AUTOSAR XML (schema 4-2-1)
# Copyright (c) 2017 Vector Informatik GmbH.
# License is restricted to the usage with CBD1500710 (D05) for MSR_Vector_SLP4.
# Please contact Vector Informatik whenever you need further information concerning the license conditions.
standard types defined: boolean, sint8, uint16, uint32, uint8
package /VehicleProject
  system System
package /NM
  nm config NmConfig: can-nm-cluster-coupling=coupled-cluster=CAN00_CAN
    can nm cluster CAN00_CAN: communication-cluster=CAN00, nm-channel-id=0, nm-user-data-length=6
      can nm node BSI: nm-if-ecu=BSI_CAN, nm-node-id=18, nm-passive-mode-enabled=true
      can nm node HDC: controller=CT_CAN00, nm-if-ecu=HDC_CAN, nm-node-id=45, nm-passive-mode-enabled=true
    nm-if-ecus:
      nm ecu BSI_CAN: nm-node-id-enabled=true, nm-passive-mode-enabled=true, nm-user-data-enabled=true
      nm ecu HDC_CAN: ecu-instance=HDC, nm-node-id-enabled=true, nm-passive-mode-enabled=true, nm-user-data-enabled=true
package /TP
  can tp config CAN00_CAN: communication-cluster=CAN00, can-tp-ecu{cycle-time-main-function=0.005, ecu-instance=HDC}
    can tp node TN_BSI
    can tp node TN_HDC: connector=CN_CAN00
package /Cluster
  can cluster CAN00: protocol-name=CAN  # COM2020_HSLS
    can physical channel CHNL: comm-connectors=CN_CAN00
      frame CAR_ACK_EVT_DEF_oCAN00: id 0x476, to HDC, frame-length=1, can-addressing-mode=STANDARD
        pdu CAR_ACK_EVT_DEF_oCAN00: length=1, minimum-delay=0, unused-bit-pattern=0
          signal REP_UCE_oCAR_ACK_EVT_DEF_oCAN00: start 0, 8 bit, little-endian, init-value=0, base-type=uint8, compu {0..255=RANGE}, transfer-property=PENDING, to HDC
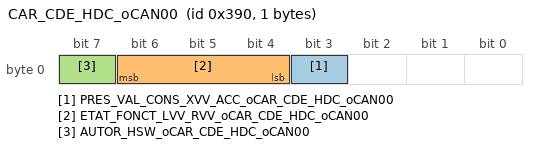
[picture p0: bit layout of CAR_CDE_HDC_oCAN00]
      frame CAR_CDE_HDC_oCAN00: id 0x390, to HDC, frame-length=1, can-addressing-mode=STANDARD
        pdu CAR_CDE_HDC_oCAN00: length=1, minimum-delay=0, transmission-mode-false-timing=event-controlled-timing={number-of-repetitions=0, repetition-period=0}, transmission-mode-true-timing=event-controlled-timing={number-of-repetitions=0, repetition-period=0}, unused-bit-pattern=0
          signal PRES_VAL_CONS_XVV_ACC_oCAR_CDE_HDC_oCAN00: start 3, 1 bit, big-endian, init-value=0, base-type=boolean, compu {0..1=RANGE}, transfer-property=TRIGGERED-ON-CHANGE-WITHOUT-REPETITION, to HDC
          signal ETAT_FONCT_LVV_RVV_oCAR_CDE_HDC_oCAN00: start 6, 3 bit, big-endian, init-value=0, base-type=uint8, compu {0..7=RANGE}, transfer-property=TRIGGERED-ON-CHANGE-WITHOUT-REPETITION, to HDC
          signal AUTOR_HSW_oCAR_CDE_HDC_oCAN00: start 7, 1 bit, big-endian, init-value=0, base-type=boolean, compu {0..1=RANGE}, transfer-property=TRIGGERED-ON-CHANGE-WITHOUT-REPETITION, to HDC
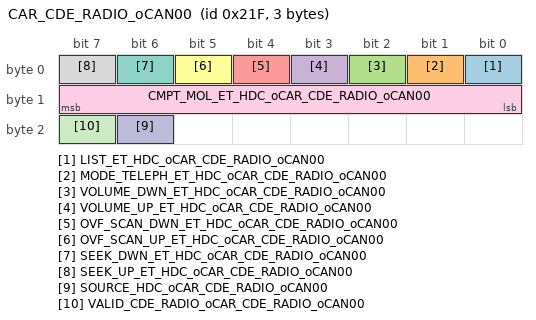
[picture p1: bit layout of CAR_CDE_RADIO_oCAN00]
      frame CAR_CDE_RADIO_oCAN00: id 0x21F, from HDC, frame-length=3, can-addressing-mode=STANDARD
        pdu CAR_CDE_RADIO_oCAN00: length=3, minimum-delay=0.05, transmission-mode-false-timing=event-controlled-timing={number-of-repetitions=0, repetition-period=0}, transmission-mode-true-timing=event-controlled-timing={number-of-repetitions=0, repetition-period=0}, unused-bit-pattern=0
          signal LIST_ET_HDC_oCAR_CDE_RADIO_oCAN00: start 0, 1 bit, big-endian, init-value=0, base-type=boolean, compu {0..1=RANGE}, transfer-property=PENDING
          signal MODE_TELEPH_ET_HDC_oCAR_CDE_RADIO_oCAN00: start 1, 1 bit, big-endian, init-value=0, base-type=boolean, compu {0..1=RANGE}, transfer-property=TRIGGERED-ON-CHANGE-WITHOUT-REPETITION
          signal VOLUME_DWN_ET_HDC_oCAR_CDE_RADIO_oCAN00: start 2, 1 bit, big-endian, init-value=0, base-type=boolean, compu {0..1=RANGE}, transfer-property=TRIGGERED-ON-CHANGE-WITHOUT-REPETITION
          signal VOLUME_UP_ET_HDC_oCAR_CDE_RADIO_oCAN00: start 3, 1 bit, big-endian, init-value=0, base-type=boolean, compu {0..1=RANGE}, transfer-property=TRIGGERED-ON-CHANGE-WITHOUT-REPETITION
          signal OVF_SCAN_DWN_ET_HDC_oCAR_CDE_RADIO_oCAN00: start 4, 1 bit, big-endian, init-value=0, base-type=boolean, compu {0..1=RANGE}, transfer-property=TRIGGERED-ON-CHANGE-WITHOUT-REPETITION
          signal OVF_SCAN_UP_ET_HDC_oCAR_CDE_RADIO_oCAN00: start 5, 1 bit, big-endian, init-value=0, base-type=boolean, compu {0..1=RANGE}, transfer-property=TRIGGERED-ON-CHANGE-WITHOUT-REPETITION
          signal SEEK_DWN_ET_HDC_oCAR_CDE_RADIO_oCAN00: start 6, 1 bit, big-endian, init-value=0, base-type=boolean, compu {0..1=RANGE}, transfer-property=TRIGGERED-ON-CHANGE-WITHOUT-REPETITION
          signal SEEK_UP_ET_HDC_oCAR_CDE_RADIO_oCAN00: start 7, 1 bit, big-endian, init-value=0, base-type=boolean, compu {0..1=RANGE}, transfer-property=TRIGGERED-ON-CHANGE-WITHOUT-REPETITION
          signal CMPT_MOL_ET_HDC_oCAR_CDE_RADIO_oCAN00: start 15, 8 bit, big-endian, init-value=0, base-type=sint8, compu {-128..127=RANGE}, transfer-property=TRIGGERED-ON-CHANGE-WITHOUT-REPETITION
          signal SOURCE_HDC_oCAR_CDE_RADIO_oCAN00: start 22, 1 bit, big-endian, init-value=0, base-type=boolean, compu {0..1=RANGE}, transfer-property=PENDING
          signal VALID_CDE_RADIO_oCAR_CDE_RADIO_oCAN00: start 23, 1 bit, big-endian, init-value=0, base-type=boolean, compu {0..1=RANGE}, transfer-property=PENDING
      frame CAR_CMD_AUTHENT_oCAN00: id 0xC2, to HDC, frame-length=8, can-addressing-mode=STANDARD
        pdu CAR_CMD_AUTHENT_oCAN00: length=8, minimum-delay=0, unused-bit-pattern=0
          signal RN_TRSP_CMD_TRSP_oCAR_CMD_AUTHENT_oCAN00: start 7, 32 bit, big-endian, init-value=0, base-type=uint32, compu {0..4294967295=RANGE}, transfer-property=PENDING, to HDC
          signal LPCRYPTE_CMD_TRSP_oCAR_CMD_AUTHENT_oCAN00: start 39, 32 bit, big-endian, init-value=0, base-type=uint32, compu {0..4294967295=RANGE}, transfer-property=PENDING, to HDC
      frame CAR_CMD_AUTHENT_MDP_AES_oCAN00: id 0x42, to HDC, frame-length=2, can-addressing-mode=STANDARD
        pdu CAR_CMD_AUTHENT_MDP_AES_oCAN00: length=2, minimum-delay=0, unused-bit-pattern=0
          signal LPCRYPTE_CMD_TRSP_AES_oCAR_CMD_AUTHENT_MDP_AES_oCAN00: start 7, 16 bit, big-endian, init-value=0, base-type=uint16, compu {0..65535=RANGE}, transfer-property=PENDING, to HDC
      frame CAR_CMD_AUTHENT_RND_AES_oCAN00: id 0x82, to HDC, frame-length=8, can-addressing-mode=STANDARD
        pdu CAR_CMD_AUTHENT_RND_AES_oCAN00: length=8, minimum-delay=0, unused-bit-pattern=0
          signal RN_TRSP_CMD_TRSP_AES_oCAR_CMD_AUTHENT_RND_AES_oCAN00: start 0, 64 bit, opaque, init-value=8 x 0, base-type=uint8_8_iso_8859_1, compu {0..18446744073709551615=RANGE}, transfer-property=PENDING, to HDC
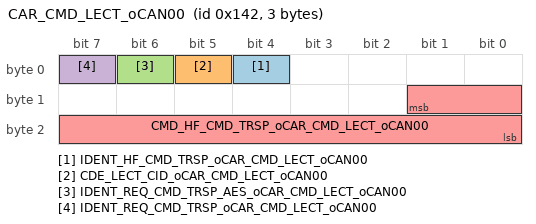
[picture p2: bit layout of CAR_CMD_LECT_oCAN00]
      frame CAR_CMD_LECT_oCAN00: id 0x142, to HDC, frame-length=3, can-addressing-mode=STANDARD
        pdu CAR_CMD_LECT_oCAN00: length=3, minimum-delay=0, unused-bit-pattern=0
          signal IDENT_HF_CMD_TRSP_oCAR_CMD_LECT_oCAN00: start 4, 1 bit, big-endian, init-value=0, base-type=boolean, compu {0..1=RANGE}, transfer-property=PENDING, to HDC
          signal CDE_LECT_CID_oCAR_CMD_LECT_oCAN00: start 5, 1 bit, big-endian, init-value=0, base-type=boolean, compu {0..1=RANGE}, transfer-property=PENDING, to HDC
          signal IDENT_REQ_CMD_TRSP_AES_oCAR_CMD_LECT_oCAN00: start 6, 1 bit, big-endian, init-value=0, base-type=boolean, compu {0..1=RANGE}, transfer-property=PENDING, to HDC
          signal IDENT_REQ_CMD_TRSP_oCAR_CMD_LECT_oCAN00: start 7, 1 bit, big-endian, init-value=0, base-type=boolean, compu {0..1=RANGE}, transfer-property=PENDING, to HDC
          signal CMD_HF_CMD_TRSP_oCAR_CMD_LECT_oCAN00: start 9, 10 bit, big-endian, init-value=0, base-type=uint16, compu {0..1023=RANGE}, transfer-property=PENDING, to HDC
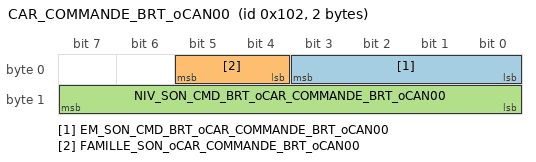
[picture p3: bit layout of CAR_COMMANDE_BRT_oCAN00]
      frame CAR_COMMANDE_BRT_oCAN00: id 0x102, to HDC, frame-length=2, can-addressing-mode=STANDARD
        pdu CAR_COMMANDE_BRT_oCAN00: length=2, minimum-delay=0, transmission-mode-false-timing=event-controlled-timing={number-of-repetitions=0, repetition-period=0}, transmission-mode-true-timing=event-controlled-timing={number-of-repetitions=0, repetition-period=0}, unused-bit-pattern=0
          signal EM_SON_CMD_BRT_oCAR_COMMANDE_BRT_oCAN00: start 3, 4 bit, big-endian, init-value=0, base-type=uint8, compu {0..15=RANGE}, transfer-property=TRIGGERED-ON-CHANGE-WITHOUT-REPETITION, to HDC
          signal FAMILLE_SON_oCAR_COMMANDE_BRT_oCAN00: start 5, 2 bit, big-endian, init-value=0, base-type=uint8, compu {0..3=RANGE}, transfer-property=PENDING, to HDC
          signal NIV_SON_CMD_BRT_oCAR_COMMANDE_BRT_oCAN00: start 15, 8 bit, big-endian, init-value=0, base-type=uint8, compu {0..255=RANGE}, transfer-property=TRIGGERED-ON-CHANGE-WITHOUT-REPETITION, to HDC
      frame CAR_COMMANDES_BSI_oCAN00: id 0x36, to HDC, frame-length=8, can-addressing-mode=STANDARD
        pdu CAR_COMMANDES_BSI_oCAN00: length=8, minimum-delay=0, transmission-mode-false-timing=event-controlled-timing={number-of-repetitions=0, repetition-period=0}, transmission-mode-true-timing=event-controlled-timing={number-of-repetitions=0, repetition-period=0}, unused-bit-pattern=0
          signal NIV_AMB_FMUX_oCAR_COMMANDES_BSI_oCAN00: start 22, 7 bit, big-endian, init-value=80, base-type=uint8, compu {0..127=RANGE}, transfer-property=PENDING, to HDC
          signal MODE_ECO_oCAR_COMMANDES_BSI_oCAN00: start 23, 1 bit, big-endian, init-value=0, base-type=boolean, compu {0..1=RANGE}, transfer-property=TRIGGERED-ON-CHANGE-WITHOUT-REPETITION, to HDC
          signal LUMINOSITE_oCAR_COMMANDES_BSI_oCAN00: start 27, 4 bit, big-endian, init-value=8, base-type=uint8, compu {0..15=RANGE}, transfer-property=PENDING, to HDC
          signal BCK_PNL_oCAR_COMMANDES_BSI_oCAN00: start 28, 1 bit, big-endian, init-value=0, base-type=boolean, compu {0..1=RANGE}, transfer-property=TRIGGERED-ON-CHANGE-WITHOUT-REPETITION, to HDC
          signal ETAT_JN_oCAR_COMMANDES_BSI_oCAN00: start 29, 1 bit, big-endian, init-value=0, base-type=boolean, compu {0..1=RANGE}, transfer-property=TRIGGERED-ON-CHANGE-WITHOUT-REPETITION, to HDC
          signal TYPE_RHEOS_oCAR_COMMANDES_BSI_oCAN00: start 30, 1 bit, big-endian, init-value=0, base-type=boolean, compu {0..1=RANGE}, transfer-property=PENDING, to HDC
          signal RESYNC_oCAR_COMMANDES_BSI_oCAN00: start 31, 1 bit, big-endian, init-value=0, base-type=boolean, compu {0..1=RANGE}, transfer-property=PENDING, to HDC
          signal PHASE_VIE_oCAR_COMMANDES_BSI_oCAN00: start 34, 3 bit, big-endian, init-value=3, base-type=uint8, compu {0..7=RANGE}, transfer-property=TRIGGERED-ON-CHANGE-WITHOUT-REPETITION, to HDC
          signal INTERD_MEMO_DEF_oCAR_COMMANDES_BSI_oCAN00: start 35, 1 bit, big-endian, init-value=0, base-type=boolean, compu {0..1=RANGE}, transfer-property=PENDING, to HDC
          signal COM_DIAG_INT_AUTOR_oCAR_COMMANDES_BSI_oCAN00: start 36, 1 bit, big-endian, init-value=0, base-type=boolean, compu {0..1=RANGE}, transfer-property=PENDING, to HDC
          signal DIAG_MUX_ON_oCAR_COMMANDES_BSI_oCAN00: start 37, 1 bit, big-endian, init-value=0, base-type=boolean, compu {0..1=RANGE}, transfer-property=PENDING, to HDC
          signal DEM_EFFAC_DEF_oCAR_COMMANDES_BSI_oCAN00: start 38, 1 bit, big-endian, init-value=0, base-type=boolean, compu {0..1=RANGE}, transfer-property=PENDING, to HDC
          signal ACTIVATION_DYN_oCAR_COMMANDES_BSI_oCAN00: start 39, 1 bit, big-endian, init-value=0, base-type=boolean, compu {0..1=RANGE}, transfer-property=PENDING, to HDC
          signal UB_MODE_HY_oCAR_COMMANDES_BSI_oCAN00: start 40, 1 bit, big-endian, init-value=0, base-type=boolean, compu {0..1=RANGE}, transfer-property=TRIGGERED-ON-CHANGE-WITHOUT-REPETITION, to HDC
          signal MODE_HY_oCAR_COMMANDES_BSI_oCAN00: start 43, 3 bit, big-endian, init-value=2, base-type=uint8, compu {0..7=RANGE}, transfer-property=TRIGGERED-ON-CHANGE-WITHOUT-REPETITION, to HDC
          signal UB_ETAT_GMP_HY_oCAR_COMMANDES_BSI_oCAN00: start 44, 1 bit, big-endian, init-value=0, base-type=boolean, compu {0..1=RANGE}, transfer-property=TRIGGERED-ON-CHANGE-WITHOUT-REPETITION, to HDC
          signal ETAT_GMP_HY_oCAR_COMMANDES_BSI_oCAN00: start 47, 3 bit, big-endian, init-value=0, base-type=uint8, compu {0..7=RANGE}, transfer-property=TRIGGERED-ON-CHANGE-WITHOUT-REPETITION, to HDC
          signal SYNC_ON_OFF_RAD_oCAR_COMMANDES_BSI_oCAN00: start 48, 1 bit, big-endian, init-value=1, base-type=boolean, compu {0..1=RANGE}, transfer-property=TRIGGERED-ON-CHANGE-WITHOUT-REPETITION, to HDC
          signal ON_OFF_RAD_oCAR_COMMANDES_BSI_oCAN00: start 49, 1 bit, big-endian, init-value=0, base-type=boolean, compu {0..1=RANGE}, transfer-property=TRIGGERED-ON-CHANGE-WITHOUT-REPETITION, to HDC
          signal PRES_MENU_PRECOND_oCAR_COMMANDES_BSI_oCAN00: start 50, 1 bit, big-endian, init-value=0, base-type=boolean, compu {0..1=RANGE}, transfer-property=PENDING, to HDC
          signal ETAT_ACTIVATION_AVR_oCAR_COMMANDES_BSI_oCAN00: start 51, 1 bit, big-endian, init-value=0, base-type=boolean, compu {0..1=RANGE}, transfer-property=TRIGGERED-ON-CHANGE-WITHOUT-REPETITION, to HDC
          signal VALID_CAFR_oCAR_COMMANDES_BSI_oCAN00: start 52, 1 bit, big-endian, init-value=0, base-type=boolean, compu {0..1=RANGE}, transfer-property=PENDING, to HDC
          signal INVIOLABILITE_AUDIO_oCAR_COMMANDES_BSI_oCAN00: start 57, 1 bit, big-endian, init-value=0, base-type=boolean, compu {0..1=RANGE}, transfer-property=PENDING, to HDC
          signal CDE_APC_oCAR_COMMANDES_BSI_oCAN00: start 59, 2 bit, big-endian, init-value=0, base-type=uint8, compu {0..3=RANGE}, transfer-property=TRIGGERED-ON-CHANGE-WITHOUT-REPETITION, to HDC
          signal SECU_ETAT_SEV_oCAR_COMMANDES_BSI_oCAN00: start 63, 4 bit, big-endian, init-value=10, base-type=uint8, compu {0..15=RANGE}, transfer-property=PENDING, to HDC
      frame CAR_DIAG_UDS_ON_CAN_oCAN00: id 0x7FF, to HDC, frame-length=8, can-addressing-mode=STANDARD
        pdu CAR_DIAG_UDS_ON_CAN_oCAN00: length=8, minimum-delay=0, unused-bit-pattern=0
          signal BLOC_UDS_oCAR_DIAG_UDS_ON_CAN_oCAN00: start 0, 64 bit, opaque, init-value=8 x 0, base-type=uint8_8_iso_8859_1, compu {0..18446744073709551615=RANGE}, transfer-property=PENDING, to HDC
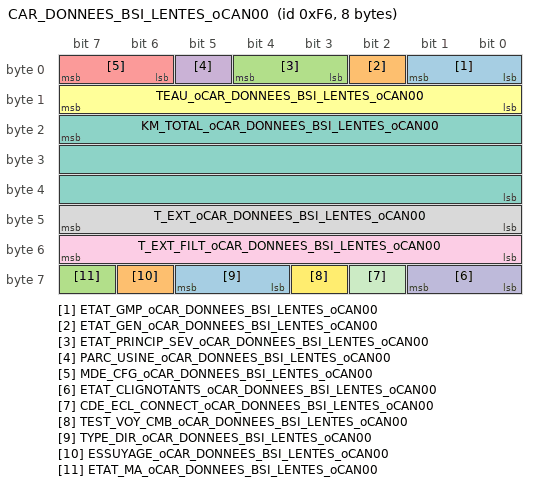
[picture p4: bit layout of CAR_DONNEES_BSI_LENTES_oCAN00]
      frame CAR_DONNEES_BSI_LENTES_oCAN00: id 0xF6, to HDC, frame-length=8, can-addressing-mode=STANDARD
        pdu CAR_DONNEES_BSI_LENTES_oCAN00: length=8, minimum-delay=0, transmission-mode-false-timing=event-controlled-timing={number-of-repetitions=0, repetition-period=0}, transmission-mode-true-timing=event-controlled-timing={number-of-repetitions=0, repetition-period=0}, unused-bit-pattern=0
          signal ETAT_GMP_oCAR_DONNEES_BSI_LENTES_oCAN00: start 1, 2 bit, big-endian, init-value=0, base-type=uint8, compu {0..3=RANGE}, transfer-property=TRIGGERED-ON-CHANGE-WITHOUT-REPETITION, to HDC
          signal ETAT_GEN_oCAR_DONNEES_BSI_LENTES_oCAN00: start 2, 1 bit, big-endian, init-value=1, base-type=boolean, compu {0..1=RANGE}, transfer-property=TRIGGERED-ON-CHANGE-WITHOUT-REPETITION, to HDC
          signal ETAT_PRINCIP_SEV_oCAR_DONNEES_BSI_LENTES_oCAN00: start 4, 2 bit, big-endian, init-value=0, base-type=uint8, compu {0..3=RANGE}, transfer-property=TRIGGERED-ON-CHANGE-WITHOUT-REPETITION, to HDC
          signal PARC_USINE_oCAR_DONNEES_BSI_LENTES_oCAN00: start 5, 1 bit, big-endian, init-value=0, base-type=boolean, compu {0..1=RANGE}, transfer-property=PENDING, to HDC
          signal MDE_CFG_oCAR_DONNEES_BSI_LENTES_oCAN00: start 7, 2 bit, big-endian, init-value=0, base-type=uint8, compu {0..3=RANGE}, transfer-property=TRIGGERED-ON-CHANGE-WITHOUT-REPETITION, to HDC
          signal TEAU_oCAR_DONNEES_BSI_LENTES_oCAN00: start 15, 8 bit, big-endian, init-value=40, base-type=uint8, compu {phys=raw-40 for raw 0..254}, transfer-property=PENDING, to HDC
          signal KM_TOTAL_oCAR_DONNEES_BSI_LENTES_oCAN00: start 23, 24 bit, big-endian, init-value=0, base-type=uint32, compu {phys=raw*0.1 for raw 0..16777213}, transfer-property=PENDING, to HDC
          signal T_EXT_oCAR_DONNEES_BSI_LENTES_oCAN00: start 47, 8 bit, big-endian, init-value=0, base-type=uint8, compu {phys=raw*0.5-40 for raw 0..250}, transfer-property=PENDING, to HDC
          signal T_EXT_FILT_oCAR_DONNEES_BSI_LENTES_oCAN00: start 55, 8 bit, big-endian, init-value=0, base-type=uint8, compu {phys=raw*0.5-40 for raw 0..250}, transfer-property=PENDING, to HDC
          signal ETAT_CLIGNOTANTS_oCAR_DONNEES_BSI_LENTES_oCAN00: start 57, 2 bit, big-endian, init-value=0, base-type=uint8, compu {0..3=RANGE}, transfer-property=TRIGGERED-ON-CHANGE-WITHOUT-REPETITION, to HDC
          signal CDE_ECL_CONNECT_oCAR_DONNEES_BSI_LENTES_oCAN00: start 58, 1 bit, big-endian, init-value=0, base-type=boolean, compu {0..1=RANGE}, transfer-property=PENDING, to HDC
          signal TEST_VOY_CMB_oCAR_DONNEES_BSI_LENTES_oCAN00: start 59, 1 bit, big-endian, init-value=0, base-type=boolean, compu {0..1=RANGE}, transfer-property=TRIGGERED-ON-CHANGE-WITHOUT-REPETITION, to HDC
          signal TYPE_DIR_oCAR_DONNEES_BSI_LENTES_oCAN00: start 61, 2 bit, big-endian, init-value=0, base-type=uint8, compu {0..3=RANGE}, transfer-property=PENDING, to HDC
          signal ESSUYAGE_oCAR_DONNEES_BSI_LENTES_oCAN00: start 62, 1 bit, big-endian, init-value=0, base-type=boolean, compu {0..1=RANGE}, transfer-property=PENDING, to HDC
          signal ETAT_MA_oCAR_DONNEES_BSI_LENTES_oCAN00: start 63, 1 bit, big-endian, init-value=0, base-type=boolean, compu {0..1=RANGE}, transfer-property=TRIGGERED-ON-CHANGE-WITHOUT-REPETITION, to HDC
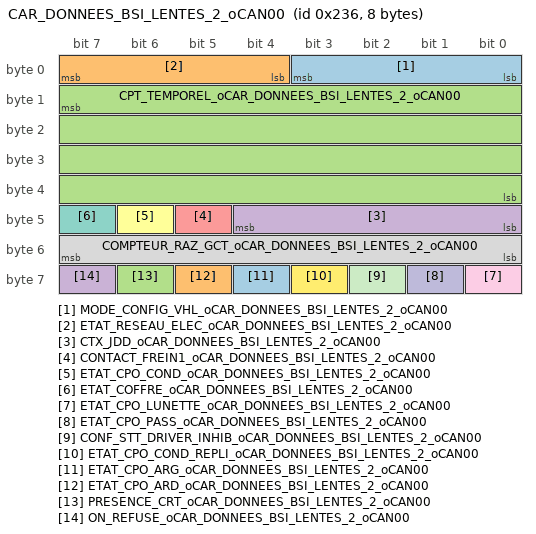
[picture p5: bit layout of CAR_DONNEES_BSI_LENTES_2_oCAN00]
      frame CAR_DONNEES_BSI_LENTES_2_oCAN00: id 0x236, to HDC, frame-length=8, can-addressing-mode=STANDARD
        pdu CAR_DONNEES_BSI_LENTES_2_oCAN00: length=8, minimum-delay=0, transmission-mode-false-timing=event-controlled-timing={number-of-repetitions=0, repetition-period=0}, transmission-mode-true-timing=event-controlled-timing={number-of-repetitions=0, repetition-period=0}, unused-bit-pattern=0
          signal MODE_CONFIG_VHL_oCAR_DONNEES_BSI_LENTES_2_oCAN00: start 3, 4 bit, big-endian, init-value=0, base-type=uint8, compu {0..15=RANGE}, transfer-property=TRIGGERED-ON-CHANGE-WITHOUT-REPETITION, to HDC
          signal ETAT_RESEAU_ELEC_oCAR_DONNEES_BSI_LENTES_2_oCAN00: start 7, 4 bit, big-endian, init-value=0, base-type=uint8, compu {0..15=RANGE}, transfer-property=TRIGGERED-ON-CHANGE-WITHOUT-REPETITION, to HDC
          signal CPT_TEMPOREL_oCAR_DONNEES_BSI_LENTES_2_oCAN00: start 15, 32 bit, big-endian, init-value=0, base-type=uint32, compu {phys=raw*0.1 for raw 0..4294967295}, transfer-property=PENDING, to HDC
          signal CTX_JDD_oCAR_DONNEES_BSI_LENTES_2_oCAN00: start 44, 5 bit, big-endian, init-value=0, base-type=uint8, compu {0..31=RANGE}, transfer-property=PENDING, to HDC
          signal CONTACT_FREIN1_oCAR_DONNEES_BSI_LENTES_2_oCAN00: start 45, 1 bit, big-endian, init-value=0, base-type=boolean, compu {0..1=RANGE}, transfer-property=PENDING, to HDC
          signal ETAT_CPO_COND_oCAR_DONNEES_BSI_LENTES_2_oCAN00: start 46, 1 bit, big-endian, init-value=0, base-type=boolean, compu {0..1=RANGE}, transfer-property=PENDING, to HDC
          signal ETAT_COFFRE_oCAR_DONNEES_BSI_LENTES_2_oCAN00: start 47, 1 bit, big-endian, init-value=0, base-type=boolean, compu {0..1=RANGE}, transfer-property=PENDING, to HDC
          signal COMPTEUR_RAZ_GCT_oCAR_DONNEES_BSI_LENTES_2_oCAN00: start 55, 8 bit, big-endian, init-value=0, base-type=uint8, compu {0..253=RANGE}, transfer-property=PENDING, to HDC
          signal ETAT_CPO_LUNETTE_oCAR_DONNEES_BSI_LENTES_2_oCAN00: start 56, 1 bit, big-endian, init-value=0, base-type=boolean, compu {0..1=RANGE}, transfer-property=PENDING, to HDC
          signal ETAT_CPO_PASS_oCAR_DONNEES_BSI_LENTES_2_oCAN00: start 57, 1 bit, big-endian, init-value=0, base-type=boolean, compu {0..1=RANGE}, transfer-property=PENDING, to HDC
          signal CONF_STT_DRIVER_INHIB_oCAR_DONNEES_BSI_LENTES_2_oCAN00: start 58, 1 bit, big-endian, init-value=0, base-type=boolean, compu {0..1=RANGE}, transfer-property=PENDING, to HDC
          signal ETAT_CPO_COND_REPLI_oCAR_DONNEES_BSI_LENTES_2_oCAN00: start 59, 1 bit, big-endian, init-value=0, base-type=boolean, compu {0..1=RANGE}, transfer-property=PENDING, to HDC
          signal ETAT_CPO_ARG_oCAR_DONNEES_BSI_LENTES_2_oCAN00: start 60, 1 bit, big-endian, init-value=0, base-type=boolean, compu {0..1=RANGE}, transfer-property=PENDING, to HDC
          signal ETAT_CPO_ARD_oCAR_DONNEES_BSI_LENTES_2_oCAN00: start 61, 1 bit, big-endian, init-value=0, base-type=boolean, compu {0..1=RANGE}, transfer-property=PENDING, to HDC
          signal PRESENCE_CRT_oCAR_DONNEES_BSI_LENTES_2_oCAN00: start 62, 1 bit, big-endian, init-value=0, base-type=boolean, compu {0..1=RANGE}, transfer-property=PENDING, to HDC
          signal ON_REFUSE_oCAR_DONNEES_BSI_LENTES_2_oCAN00: start 63, 1 bit, big-endian, init-value=0, base-type=boolean, compu {0..1=RANGE}, transfer-property=PENDING, to HDC
      frame CAR_ETAT_HDC_oCAN00: id 0x94, from HDC, frame-length=8, can-addressing-mode=STANDARD
        pdu CAR_ETAT_HDC_oCAN00: length=8, minimum-delay=0.03, transmission-mode-false-timing=event-controlled-timing={number-of-repetitions=0, repetition-period=0}, transmission-mode-true-timing=event-controlled-timing={number-of-repetitions=0, repetition-period=0}, unused-bit-pattern=0
          signal PSH_GH_ET_HDC_ETAT_oCAR_ETAT_HDC_oCAN00: start 0, 1 bit, big-endian, init-value=0, base-type=boolean, compu {0..1=RANGE}, transfer-property=TRIGGERED-ON-CHANGE-WITHOUT-REPETITION
          signal BRD_ET_HDC_oCAR_ETAT_HDC_oCAN00: start 2, 2 bit, big-endian, init-value=0, base-type=uint8, compu {0..3=RANGE}, transfer-property=TRIGGERED-ON-CHANGE-WITHOUT-REPETITION
          signal APPEL_PH_ET_HDC_oCAR_ETAT_HDC_oCAN00: start 3, 1 bit, big-endian, init-value=0, base-type=boolean, compu {0..1=RANGE}, transfer-property=TRIGGERED-ON-CHANGE-WITHOUT-REPETITION
          signal INV_CDPH_ET_HDC_oCAR_ETAT_HDC_oCAN00: start 4, 1 bit, big-endian, init-value=0, base-type=boolean, compu {0..1=RANGE}, transfer-property=TRIGGERED-ON-CHANGE-WITHOUT-REPETITION
          signal VILLE_ROUTE_ET_HDC_oCAR_ETAT_HDC_oCAN00: start 7, 3 bit, big-endian, init-value=0, base-type=uint8, compu {0..7=RANGE}, transfer-property=TRIGGERED-ON-CHANGE-WITHOUT-REPETITION
          signal PSH_DT_ET_HDC_oCAR_ETAT_HDC_oCAN00: start 8, 1 bit, big-endian, init-value=0, base-type=boolean, compu {0..1=RANGE}, transfer-property=TRIGGERED-ON-CHANGE-WITHOUT-REPETITION
          signal ROT_2_CRAN_ESS_oCAR_ETAT_HDC_oCAN00: start 9, 1 bit, big-endian, init-value=0, base-type=boolean, compu {0..1=RANGE}, transfer-property=TRIGGERED-ON-CHANGE-WITHOUT-REPETITION
          signal ROT_1_CRAN_ESS_oCAR_ETAT_HDC_oCAN00: start 10, 1 bit, big-endian, init-value=0, base-type=boolean, compu {0..1=RANGE}, transfer-property=TRIGGERED-ON-CHANGE-WITHOUT-REPETITION
          signal POS_TIR_UN_CRAN_oCAR_ETAT_HDC_oCAN00: start 11, 1 bit, big-endian, init-value=0, base-type=boolean, compu {0..1=RANGE}, transfer-property=TRIGGERED-ON-CHANGE-WITHOUT-REPETITION
          signal POS_BAS_UN_CRAN_oCAR_ETAT_HDC_oCAN00: start 12, 1 bit, big-endian, init-value=0, base-type=boolean, compu {0..1=RANGE}, transfer-property=TRIGGERED-ON-CHANGE-WITHOUT-REPETITION
          signal ESS_AV_ET_HDC_oCAR_ETAT_HDC_oCAN00: start 15, 3 bit, big-endian, init-value=0, base-type=uint8, compu {0..7=RANGE}, transfer-property=TRIGGERED-ON-CHANGE-WITHOUT-REPETITION
          signal DMD_PLAF_VOLANT_oCAR_ETAT_HDC_oCAN00: start 16, 1 bit, big-endian, init-value=0, base-type=boolean, compu {0..1=RANGE}, transfer-property=TRIGGERED-ON-CHANGE-WITHOUT-REPETITION
          signal VILL_ROUTE_ET_4POS_oCAR_ETAT_HDC_oCAN00: start 20, 4 bit, big-endian, init-value=0, base-type=uint8, compu {0..15=RANGE}, transfer-property=TRIGGERED-ON-CHANGE-WITHOUT-REPETITION
          signal DEFAUT_HDC_IHM_RHEOST_oCAR_ETAT_HDC_oCAN00: start 21, 1 bit, big-endian, init-value=0, base-type=boolean, compu {0..1=RANGE}, transfer-property=TRIGGERED-ON-CHANGE-WITHOUT-REPETITION
          signal CDE_CLG_ET_HDC_oCAR_ETAT_HDC_oCAN00: start 23, 2 bit, big-endian, init-value=0, base-type=uint8, compu {0..3=RANGE}, transfer-property=TRIGGERED-ON-CHANGE-WITHOUT-REPETITION
          signal PUSH_ARTIV_oCAR_ETAT_HDC_oCAN00: start 24, 1 bit, big-endian, init-value=0, base-type=boolean, compu {0..1=RANGE}, transfer-property=TRIGGERED-ON-CHANGE-WITHOUT-REPETITION
          signal ACC_DWN_ET_HDC_oCAR_ETAT_HDC_oCAN00: start 25, 1 bit, big-endian, init-value=0, base-type=boolean, compu {0..1=RANGE}, transfer-property=TRIGGERED-ON-CHANGE-WITHOUT-REPETITION
          signal ACC_UP_ET_HDC_oCAR_ETAT_HDC_oCAN00: start 26, 1 bit, big-endian, init-value=0, base-type=boolean, compu {0..1=RANGE}, transfer-property=TRIGGERED-ON-CHANGE-WITHOUT-REPETITION
          signal DESACTIV_ET_HDC_oCAR_ETAT_HDC_oCAN00: start 27, 1 bit, big-endian, init-value=0, base-type=boolean, compu {0..1=RANGE}, transfer-property=TRIGGERED-ON-CHANGE-WITHOUT-REPETITION
          signal SPEED_DWN_ET_HDC_oCAR_ETAT_HDC_oCAN00: start 28, 1 bit, big-endian, init-value=0, base-type=boolean, compu {0..1=RANGE}, transfer-property=TRIGGERED-ON-CHANGE-WITHOUT-REPETITION
          signal SPEED_UP_ET_HDC_oCAR_ETAT_HDC_oCAN00: start 29, 1 bit, big-endian, init-value=0, base-type=boolean, compu {0..1=RANGE}, transfer-property=TRIGGERED-ON-CHANGE-WITHOUT-REPETITION
          signal LVV_RVV_HDC_oCAR_ETAT_HDC_oCAN00: start 31, 2 bit, big-endian, init-value=0, base-type=uint8, compu {0..3=RANGE}, transfer-property=TRIGGERED-ON-CHANGE-WITHOUT-REPETITION
          signal PUSH_DESELECTION_LVV_RVV_oCAR_ETAT_HDC_oCAN00: start 32, 1 bit, big-endian, init-value=0, base-type=boolean, compu {0..1=RANGE}, transfer-property=TRIGGERED-ON-CHANGE-WITHOUT-REPETITION
          signal PUSH_CYCLAGE_LVV_RVV_oCAR_ETAT_HDC_oCAN00: start 33, 1 bit, big-endian, init-value=0, base-type=boolean, compu {0..1=RANGE}, transfer-property=TRIGGERED-ON-CHANGE-WITHOUT-REPETITION
          signal OVF_RHEOST_INF_oCAR_ETAT_HDC_oCAN00: start 34, 1 bit, big-endian, init-value=0, base-type=boolean, compu {0..1=RANGE}, transfer-property=TRIGGERED-ON-CHANGE-WITHOUT-REPETITION
          signal OVF_RHEOST_SUP_oCAR_ETAT_HDC_oCAN00: start 35, 1 bit, big-endian, init-value=0, base-type=boolean, compu {0..1=RANGE}, transfer-property=TRIGGERED-ON-CHANGE-WITHOUT-REPETITION
          signal TOUCHE_CONFIG_oCAR_ETAT_HDC_oCAN00: start 36, 1 bit, big-endian, init-value=0, base-type=boolean, compu {0..1=RANGE}, transfer-property=TRIGGERED-ON-CHANGE-WITHOUT-REPETITION
          signal PLACE_DISPO_oCAR_ETAT_HDC_oCAN00: start 37, 1 bit, big-endian, init-value=0, base-type=boolean, compu {0..1=RANGE}, transfer-property=TRIGGERED-ON-CHANGE-WITHOUT-REPETITION
          signal HDC_CDE_VOCALE_ET_VMF_oCAR_ETAT_HDC_oCAN00: start 38, 1 bit, big-endian, init-value=0, base-type=boolean, compu {0..1=RANGE}, transfer-property=TRIGGERED-ON-CHANGE-WITHOUT-REPETITION
          signal CDE_AVERT_ET_HDC_oCAR_ETAT_HDC_oCAN00: start 39, 1 bit, big-endian, init-value=0, base-type=boolean, compu {0..1=RANGE}, transfer-property=TRIGGERED-ON-CHANGE-WITHOUT-REPETITION
          signal CMPT_RHEOSTATAGE_oCAR_ETAT_HDC_oCAN00: start 47, 8 bit, big-endian, init-value=0, base-type=sint8, compu {-128..127=RANGE}, transfer-property=TRIGGERED-ON-CHANGE-WITHOUT-REPETITION
          signal PSH_VOL_oCAR_ETAT_HDC_oCAN00: start 51, 4 bit, big-endian, init-value=0, base-type=uint8, compu {0..15=RANGE}, transfer-property=TRIGGERED-ON-CHANGE-WITHOUT-REPETITION
          signal PUSH_SEL_RVV_oCAR_ETAT_HDC_oCAN00: start 52, 1 bit, big-endian, init-value=0, base-type=boolean, compu {0..1=RANGE}, transfer-property=TRIGGERED-ON-CHANGE-WITHOUT-REPETITION
          signal PUSH_SEL_LVV_oCAR_ETAT_HDC_oCAN00: start 53, 1 bit, big-endian, init-value=0, base-type=boolean, compu {0..1=RANGE}, transfer-property=TRIGGERED-ON-CHANGE-WITHOUT-REPETITION
          signal REVEIL_HDC_oCAR_ETAT_HDC_oCAN00: start 54, 1 bit, big-endian, init-value=0, base-type=boolean, compu {0..1=RANGE}, transfer-property=TRIGGERED-ON-CHANGE-WITHOUT-REPETITION
          signal DMD_BLACK_PANEL_oCAR_ETAT_HDC_oCAN00: start 55, 1 bit, big-endian, init-value=0, base-type=boolean, compu {0..1=RANGE}, transfer-property=TRIGGERED-ON-CHANGE-WITHOUT-REPETITION
          signal LOUDSPEAKER_DEFAULT_oCAR_ETAT_HDC_oCAN00: start 57, 1 bit, big-endian, init-value=0, base-type=boolean, compu {0..1=RANGE}, transfer-property=TRIGGERED-ON-CHANGE-WITHOUT-REPETITION
          signal SENSI_ESS_HDC_oCAR_ETAT_HDC_oCAN00: start 61, 3 bit, big-endian, init-value=0, base-type=uint8, compu {0..7=RANGE}, transfer-property=TRIGGERED-ON-CHANGE-WITHOUT-REPETITION
          signal DEFAUT_HDC_ARC_oCAR_ETAT_HDC_oCAN00: start 62, 1 bit, big-endian, init-value=0, base-type=boolean, compu {0..1=RANGE}, transfer-property=TRIGGERED-ON-CHANGE-WITHOUT-REPETITION
          signal DMD_XVV_PROG_oCAR_ETAT_HDC_oCAN00: start 63, 1 bit, big-endian, init-value=0, base-type=boolean, compu {0..1=RANGE}, transfer-property=TRIGGERED-ON-CHANGE-WITHOUT-REPETITION
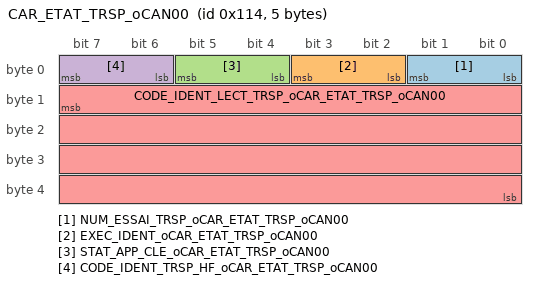
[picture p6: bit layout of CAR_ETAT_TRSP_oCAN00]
      frame CAR_ETAT_TRSP_oCAN00: id 0x114, from HDC, frame-length=5, can-addressing-mode=STANDARD
        pdu CAR_ETAT_TRSP_oCAN00: length=5, minimum-delay=0, transmission-mode-false-timing=event-controlled-timing={number-of-repetitions=0, repetition-period=0}, transmission-mode-true-timing=event-controlled-timing={number-of-repetitions=0, repetition-period=0}, unused-bit-pattern=0
          signal NUM_ESSAI_TRSP_oCAR_ETAT_TRSP_oCAN00: start 1, 2 bit, big-endian, init-value=0, base-type=uint8, compu {0..3=RANGE}, transfer-property=TRIGGERED-WITHOUT-REPETITION
          signal EXEC_IDENT_oCAR_ETAT_TRSP_oCAN00: start 3, 2 bit, big-endian, init-value=0, base-type=uint8, compu {0..3=RANGE}, transfer-property=TRIGGERED-WITHOUT-REPETITION
          signal STAT_APP_CLE_oCAR_ETAT_TRSP_oCAN00: start 5, 2 bit, big-endian, init-value=0, base-type=uint8, compu {0..3=RANGE}, transfer-property=TRIGGERED-WITHOUT-REPETITION
          signal CODE_IDENT_TRSP_HF_oCAR_ETAT_TRSP_oCAN00: start 7, 2 bit, big-endian, init-value=0, base-type=uint8, compu {0..3=RANGE}, transfer-property=TRIGGERED-WITHOUT-REPETITION
          signal CODE_IDENT_LECT_TRSP_oCAR_ETAT_TRSP_oCAN00: start 15, 32 bit, big-endian, init-value=0, base-type=uint32, compu {0..4294967295=RANGE}, transfer-property=PENDING
      frame CAR_EVT_DEFAUT_HDC_oCAN00: id 0x482, from HDC, frame-length=8, can-addressing-mode=STANDARD
        pdu CAR_EVT_DEFAUT_HDC_oCAN00: length=8, minimum-delay=0, transmission-mode-false-timing=event-controlled-timing={number-of-repetitions=0, repetition-period=0}, transmission-mode-true-timing=event-controlled-timing={number-of-repetitions=0, repetition-period=0}, unused-bit-pattern=0
          signal BLOC_DIAG_oCAR_EVT_DEFAUT_HDC_oCAN00: start 4, 60 bit, opaque, init-value=8 x 0, base-type=uint8_8_iso_8859_1, compu {0..1152921504606846975=RANGE}, transfer-property=PENDING
          signal NUM_TRAME_oCAR_EVT_DEFAUT_HDC_oCAN00: start 5, 2 bit, big-endian, init-value=0, base-type=uint8, compu {0..3=RANGE}, transfer-property=TRIGGERED-WITHOUT-REPETITION
          signal NB_TRAME_oCAR_EVT_DEFAUT_HDC_oCAN00: start 7, 2 bit, big-endian, init-value=0, base-type=uint8, compu {0..3=RANGE}, transfer-property=PENDING
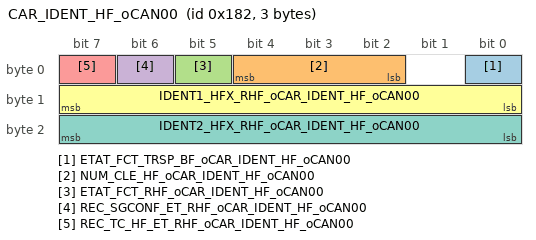
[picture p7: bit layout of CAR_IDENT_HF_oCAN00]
      frame CAR_IDENT_HF_oCAN00: id 0x182, to HDC, frame-length=3, can-addressing-mode=STANDARD
        pdu CAR_IDENT_HF_oCAN00: length=3, minimum-delay=0, transmission-mode-false-timing=event-controlled-timing={number-of-repetitions=0, repetition-period=0}, transmission-mode-true-timing=event-controlled-timing={number-of-repetitions=0, repetition-period=0}, unused-bit-pattern=0
          signal ETAT_FCT_TRSP_BF_oCAR_IDENT_HF_oCAN00: start 0, 1 bit, big-endian, init-value=1, base-type=boolean, compu {0..1=RANGE}, transfer-property=TRIGGERED-ON-CHANGE-WITHOUT-REPETITION, to HDC
          signal NUM_CLE_HF_oCAR_IDENT_HF_oCAN00: start 4, 3 bit, big-endian, init-value=1, base-type=uint8, compu {1..5=RANGE}, transfer-property=PENDING, to HDC
          signal ETAT_FCT_RHF_oCAR_IDENT_HF_oCAN00: start 5, 1 bit, big-endian, init-value=1, base-type=boolean, compu {0..1=RANGE}, transfer-property=PENDING, to HDC
          signal REC_SGCONF_ET_RHF_oCAR_IDENT_HF_oCAN00: start 6, 1 bit, big-endian, init-value=0, base-type=boolean, compu {0..1=RANGE}, transfer-property=PENDING, to HDC
          signal REC_TC_HF_ET_RHF_oCAR_IDENT_HF_oCAN00: start 7, 1 bit, big-endian, init-value=1, base-type=boolean, compu {0..1=RANGE}, transfer-property=TRIGGERED-ON-CHANGE-WITHOUT-REPETITION, to HDC
          signal IDENT1_HFX_RHF_oCAR_IDENT_HF_oCAN00: start 15, 8 bit, big-endian, init-value=0, base-type=uint8, compu {0..255=RANGE}, transfer-property=TRIGGERED-ON-CHANGE-WITHOUT-REPETITION, to HDC
          signal IDENT2_HFX_RHF_oCAR_IDENT_HF_oCAN00: start 23, 8 bit, big-endian, init-value=0, base-type=uint8, compu {0..255=RANGE}, transfer-property=TRIGGERED-ON-CHANGE-WITHOUT-REPETITION, to HDC
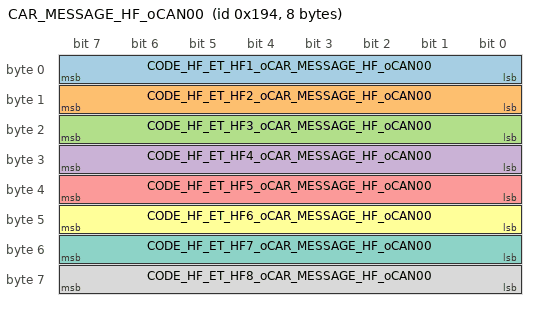
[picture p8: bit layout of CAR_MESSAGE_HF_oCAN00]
      frame CAR_MESSAGE_HF_oCAN00: id 0x194, from HDC, frame-length=8, can-addressing-mode=STANDARD
        pdu CAR_MESSAGE_HF_oCAN00: length=8, minimum-delay=0, transmission-mode-false-timing=event-controlled-timing={number-of-repetitions=0, repetition-period=0}, transmission-mode-true-timing=event-controlled-timing={number-of-repetitions=0, repetition-period=0}, unused-bit-pattern=0
          signal CODE_HF_ET_HF1_oCAR_MESSAGE_HF_oCAN00: start 7, 8 bit, big-endian, init-value=0, base-type=uint8, compu {0..255=RANGE}, transfer-property=TRIGGERED-WITHOUT-REPETITION
          signal CODE_HF_ET_HF2_oCAR_MESSAGE_HF_oCAN00: start 15, 8 bit, big-endian, init-value=0, base-type=uint8, compu {0..255=RANGE}, transfer-property=TRIGGERED-WITHOUT-REPETITION
          signal CODE_HF_ET_HF3_oCAR_MESSAGE_HF_oCAN00: start 23, 8 bit, big-endian, init-value=0, base-type=uint8, compu {0..255=RANGE}, transfer-property=TRIGGERED-WITHOUT-REPETITION
          signal CODE_HF_ET_HF4_oCAR_MESSAGE_HF_oCAN00: start 31, 8 bit, big-endian, init-value=0, base-type=uint8, compu {0..255=RANGE}, transfer-property=TRIGGERED-WITHOUT-REPETITION
          signal CODE_HF_ET_HF5_oCAR_MESSAGE_HF_oCAN00: start 39, 8 bit, big-endian, init-value=0, base-type=uint8, compu {0..255=RANGE}, transfer-property=TRIGGERED-WITHOUT-REPETITION
          signal CODE_HF_ET_HF6_oCAR_MESSAGE_HF_oCAN00: start 47, 8 bit, big-endian, init-value=0, base-type=uint8, compu {0..255=RANGE}, transfer-property=TRIGGERED-WITHOUT-REPETITION
          signal CODE_HF_ET_HF7_oCAR_MESSAGE_HF_oCAN00: start 55, 8 bit, big-endian, init-value=0, base-type=uint8, compu {0..255=RANGE}, transfer-property=TRIGGERED-WITHOUT-REPETITION
          signal CODE_HF_ET_HF8_oCAR_MESSAGE_HF_oCAN00: start 63, 8 bit, big-endian, init-value=0, base-type=uint8, compu {0..255=RANGE}, transfer-property=TRIGGERED-WITHOUT-REPETITION
          mapping SG_CODE_HF_ET_HF_GROUP: i-signal-group=SG_CODE_HF_ET_HF_GROUP_oCAR_MESSAGE_HF_oCAN00, transfer-property=PENDING
      frame CAR_PROG_TRSP_AUTHENT_oCAN00: id 0x2C2, to HDC, frame-length=7, can-addressing-mode=STANDARD
        pdu CAR_PROG_TRSP_AUTHENT_oCAN00: length=7, minimum-delay=0, unused-bit-pattern=0
          signal MARQUEUR_DEBUT_oCAR_PROG_TRSP_AUTHENT_oCAN00: start 7, 8 bit, big-endian, init-value=0, base-type=uint8, compu {0..252=RANGE}, transfer-property=PENDING, to HDC
          signal AUTHENT_PROG_TRSP_oCAR_PROG_TRSP_AUTHENT_oCAN00: start 8, 48 bit, opaque, init-value=6 x 0, base-type=uint8_6_iso_8859_1, compu {0..281474976710655=RANGE}, transfer-property=PENDING, to HDC
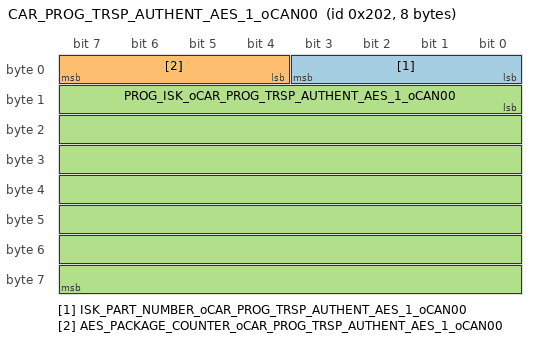
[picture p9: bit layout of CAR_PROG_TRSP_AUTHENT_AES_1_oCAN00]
      frame CAR_PROG_TRSP_AUTHENT_AES_1_oCAN00: id 0x202, to HDC, frame-length=8, can-addressing-mode=STANDARD
        pdu CAR_PROG_TRSP_AUTHENT_AES_1_oCAN00: length=8, minimum-delay=0, unused-bit-pattern=0
          signal ISK_PART_NUMBER_oCAR_PROG_TRSP_AUTHENT_AES_1_oCAN00: start 3, 4 bit, big-endian, init-value=0, base-type=uint8, compu {0..15=RANGE}, transfer-property=PENDING, to HDC
          signal AES_PACKAGE_COUNTER_oCAR_PROG_TRSP_AUTHENT_AES_1_oCAN00: start 7, 4 bit, big-endian, init-value=0, base-type=uint8, compu {0..15=RANGE}, transfer-property=PENDING, to HDC
          signal PROG_ISK_oCAR_PROG_TRSP_AUTHENT_AES_1_oCAN00: start 8, 56 bit, opaque, init-value=7 x 0, base-type=uint8_7_iso_8859_1, compu {0..72057594037927896=RANGE}, transfer-property=PENDING, to HDC
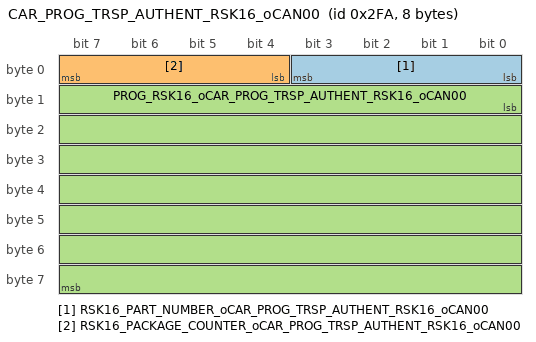
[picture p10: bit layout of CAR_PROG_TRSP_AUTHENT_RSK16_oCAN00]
      frame CAR_PROG_TRSP_AUTHENT_RSK16_oCAN00: id 0x2FA, to HDC, frame-length=8, can-addressing-mode=STANDARD
        pdu CAR_PROG_TRSP_AUTHENT_RSK16_oCAN00: length=8, minimum-delay=0, unused-bit-pattern=0
          signal RSK16_PART_NUMBER_oCAR_PROG_TRSP_AUTHENT_RSK16_oCAN00: start 3, 4 bit, big-endian, init-value=0, base-type=uint8, compu {0..15=RANGE}, transfer-property=PENDING, to HDC
          signal RSK16_PACKAGE_COUNTER_oCAR_PROG_TRSP_AUTHENT_RSK16_oCAN00: start 7, 4 bit, big-endian, init-value=0, base-type=uint8, compu {0..15=RANGE}, transfer-property=PENDING, to HDC
          signal PROG_RSK16_oCAR_PROG_TRSP_AUTHENT_RSK16_oCAN00: start 8, 56 bit, opaque, init-value=7 x 0, base-type=uint8_7_iso_8859_1, compu {0..72057594037927896=RANGE}, transfer-property=PENDING, to HDC
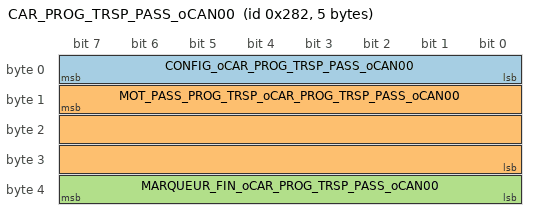
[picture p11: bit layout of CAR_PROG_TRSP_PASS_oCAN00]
      frame CAR_PROG_TRSP_PASS_oCAN00: id 0x282, to HDC, frame-length=5, can-addressing-mode=STANDARD
        pdu CAR_PROG_TRSP_PASS_oCAN00: length=5, minimum-delay=0, unused-bit-pattern=0
          signal CONFIG_oCAR_PROG_TRSP_PASS_oCAN00: start 7, 8 bit, big-endian, init-value=0, base-type=uint8, compu {0..255=RANGE}, transfer-property=PENDING, to HDC
          signal MOT_PASS_PROG_TRSP_oCAR_PROG_TRSP_PASS_oCAN00: start 15, 24 bit, big-endian, init-value=0, base-type=uint32, compu {0..16777215=RANGE}, transfer-property=PENDING, to HDC
          signal MARQUEUR_FIN_oCAR_PROG_TRSP_PASS_oCAN00: start 39, 8 bit, big-endian, init-value=0, base-type=uint8, compu {0..252=RANGE}, transfer-property=PENDING, to HDC
      frame CAR_REP_DIAG_HDC_oCAN00: id 0x642, from HDC, frame-length=8, can-addressing-mode=STANDARD
        n pdu CAR_REP_DIAG_HDC_Tp_oCAN00: length=8
      frame CAR_REP_DIAG_HDC_VCI_oCAN00: id 0x628, from HDC, frame-length=8, can-addressing-mode=STANDARD
        n pdu CAR_REP_DIAG_HDC_VCI_Tp_oCAN00: length=8
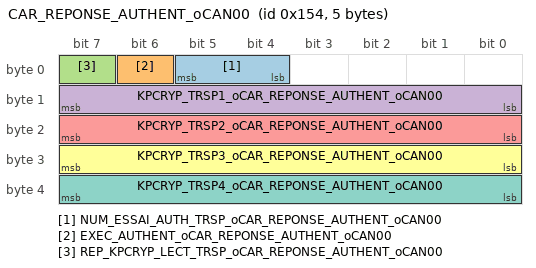
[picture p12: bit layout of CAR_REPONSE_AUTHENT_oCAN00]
      frame CAR_REPONSE_AUTHENT_oCAN00: id 0x154, from HDC, frame-length=5, can-addressing-mode=STANDARD
        pdu CAR_REPONSE_AUTHENT_oCAN00: length=5, minimum-delay=0, unused-bit-pattern=0
          signal NUM_ESSAI_AUTH_TRSP_oCAR_REPONSE_AUTHENT_oCAN00: start 5, 2 bit, big-endian, init-value=0, base-type=uint8, compu {0..3=RANGE}, transfer-property=PENDING
          signal EXEC_AUTHENT_oCAR_REPONSE_AUTHENT_oCAN00: start 6, 1 bit, big-endian, init-value=0, base-type=boolean, compu {0..1=RANGE}, transfer-property=PENDING
          signal REP_KPCRYP_LECT_TRSP_oCAR_REPONSE_AUTHENT_oCAN00: start 7, 1 bit, big-endian, init-value=0, base-type=boolean, compu {0..1=RANGE}, transfer-property=PENDING
          signal KPCRYP_TRSP1_oCAR_REPONSE_AUTHENT_oCAN00: start 15, 8 bit, big-endian, init-value=0, base-type=uint8, compu {0..255=RANGE}, transfer-property=PENDING
          signal KPCRYP_TRSP2_oCAR_REPONSE_AUTHENT_oCAN00: start 23, 8 bit, big-endian, init-value=0, base-type=uint8, compu {0..255=RANGE}, transfer-property=PENDING
          signal KPCRYP_TRSP3_oCAR_REPONSE_AUTHENT_oCAN00: start 31, 8 bit, big-endian, init-value=0, base-type=uint8, compu {0..255=RANGE}, transfer-property=PENDING
          signal KPCRYP_TRSP4_oCAR_REPONSE_AUTHENT_oCAN00: start 39, 8 bit, big-endian, init-value=0, base-type=uint8, compu {0..255=RANGE}, transfer-property=PENDING
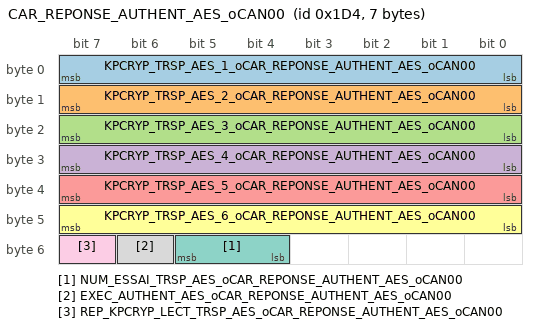
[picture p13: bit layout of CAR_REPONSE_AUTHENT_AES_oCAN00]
      frame CAR_REPONSE_AUTHENT_AES_oCAN00: id 0x1D4, from HDC, frame-length=7, can-addressing-mode=STANDARD
        pdu CAR_REPONSE_AUTHENT_AES_oCAN00: length=7, minimum-delay=0, transmission-mode-false-timing=event-controlled-timing={number-of-repetitions=0, repetition-period=0}, transmission-mode-true-timing=event-controlled-timing={number-of-repetitions=0, repetition-period=0}, unused-bit-pattern=0
          signal KPCRYP_TRSP_AES_1_oCAR_REPONSE_AUTHENT_AES_oCAN00: start 7, 8 bit, big-endian, init-value=0, base-type=uint8, compu {0..255=RANGE}, transfer-property=PENDING
          signal KPCRYP_TRSP_AES_2_oCAR_REPONSE_AUTHENT_AES_oCAN00: start 15, 8 bit, big-endian, init-value=0, base-type=uint8, compu {0..255=RANGE}, transfer-property=PENDING
          signal KPCRYP_TRSP_AES_3_oCAR_REPONSE_AUTHENT_AES_oCAN00: start 23, 8 bit, big-endian, init-value=0, base-type=uint8, compu {0..255=RANGE}, transfer-property=PENDING
          signal KPCRYP_TRSP_AES_4_oCAR_REPONSE_AUTHENT_AES_oCAN00: start 31, 8 bit, big-endian, init-value=0, base-type=uint8, compu {0..255=RANGE}, transfer-property=PENDING
          signal KPCRYP_TRSP_AES_5_oCAR_REPONSE_AUTHENT_AES_oCAN00: start 39, 8 bit, big-endian, init-value=0, base-type=uint8, compu {0..255=RANGE}, transfer-property=PENDING
          signal KPCRYP_TRSP_AES_6_oCAR_REPONSE_AUTHENT_AES_oCAN00: start 47, 8 bit, big-endian, init-value=0, base-type=uint8, compu {0..255=RANGE}, transfer-property=PENDING
          signal NUM_ESSAI_TRSP_AES_oCAR_REPONSE_AUTHENT_AES_oCAN00: start 53, 2 bit, big-endian, init-value=0, base-type=uint8, compu {0..3=RANGE}, transfer-property=TRIGGERED-WITHOUT-REPETITION
          signal EXEC_AUTHENT_AES_oCAR_REPONSE_AUTHENT_AES_oCAN00: start 54, 1 bit, big-endian, init-value=0, base-type=boolean, compu {0..1=RANGE}, transfer-property=TRIGGERED-WITHOUT-REPETITION
          signal REP_KPCRYP_LECT_TRSP_AES_oCAR_REPONSE_AUTHENT_AES_oCAN00: start 55, 1 bit, big-endian, init-value=0, base-type=boolean, compu {0..1=RANGE}, transfer-property=TRIGGERED-WITHOUT-REPETITION
      frame CAR_REQ_DIAG_HDC_oCAN00: id 0x742, to HDC, frame-length=8, can-addressing-mode=STANDARD
        n pdu CAR_REQ_DIAG_HDC_Tp_oCAN00: length=8
      frame CAR_REQ_DIAG_HDC_VCI_oCAN00: id 0x6C8, to HDC, frame-length=8, can-addressing-mode=STANDARD
        n pdu CAR_REQ_DIAG_HDC_VCI_Tp_oCAN00: length=8
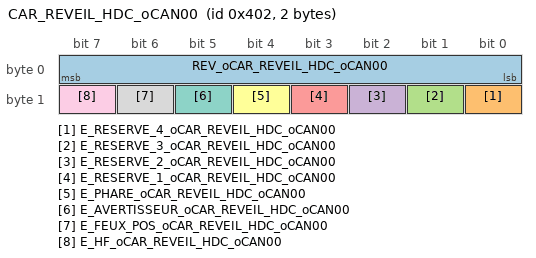
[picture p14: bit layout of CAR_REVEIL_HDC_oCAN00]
      frame CAR_REVEIL_HDC_oCAN00: id 0x402, from HDC, frame-length=2, can-addressing-mode=STANDARD
        pdu CAR_REVEIL_HDC_oCAN00: length=2, minimum-delay=0, transmission-mode-false-timing=event-controlled-timing={number-of-repetitions=0, repetition-period=0}, transmission-mode-true-timing=event-controlled-timing={number-of-repetitions=0, repetition-period=0}, unused-bit-pattern=0
          signal REV_oCAR_REVEIL_HDC_oCAN00: start 7, 8 bit, big-endian, init-value=0, base-type=uint8, compu {0..255=RANGE}, transfer-property=PENDING
          signal E_RESERVE_4_oCAR_REVEIL_HDC_oCAN00: start 8, 1 bit, big-endian, init-value=0, base-type=boolean, compu {0..1=RANGE}, transfer-property=PENDING
          signal E_RESERVE_3_oCAR_REVEIL_HDC_oCAN00: start 9, 1 bit, big-endian, init-value=0, base-type=boolean, compu {0..1=RANGE}, transfer-property=PENDING
          signal E_RESERVE_2_oCAR_REVEIL_HDC_oCAN00: start 10, 1 bit, big-endian, init-value=0, base-type=boolean, compu {0..1=RANGE}, transfer-property=PENDING
          signal E_RESERVE_1_oCAR_REVEIL_HDC_oCAN00: start 11, 1 bit, big-endian, init-value=0, base-type=boolean, compu {0..1=RANGE}, transfer-property=PENDING
          signal E_PHARE_oCAR_REVEIL_HDC_oCAN00: start 12, 1 bit, big-endian, init-value=0, base-type=boolean, compu {0..1=RANGE}, transfer-property=TRIGGERED-WITHOUT-REPETITION
          signal E_AVERTISSEUR_oCAR_REVEIL_HDC_oCAN00: start 13, 1 bit, big-endian, init-value=0, base-type=boolean, compu {0..1=RANGE}, transfer-property=TRIGGERED-WITHOUT-REPETITION
          signal E_FEUX_POS_oCAR_REVEIL_HDC_oCAN00: start 14, 1 bit, big-endian, init-value=0, base-type=boolean, compu {0..1=RANGE}, transfer-property=TRIGGERED-WITHOUT-REPETITION
          signal E_HF_oCAR_REVEIL_HDC_oCAN00: start 15, 1 bit, big-endian, init-value=0, base-type=boolean, compu {0..1=RANGE}, transfer-property=TRIGGERED-WITHOUT-REPETITION
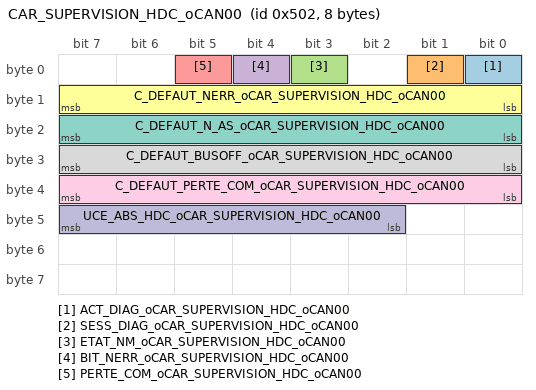
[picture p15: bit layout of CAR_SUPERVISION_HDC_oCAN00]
      frame CAR_SUPERVISION_HDC_oCAN00: id 0x502, from HDC, frame-length=8, can-addressing-mode=STANDARD
        pdu CAR_SUPERVISION_HDC_oCAN00: length=8, minimum-delay=0.025, transmission-mode-false-timing=cyclic-timing={time-offset=0, time-period=1}, transmission-mode-true-timing=cyclic-timing={time-offset=0, time-period=1}, unused-bit-pattern=0
          signal ACT_DIAG_oCAR_SUPERVISION_HDC_oCAN00: start 0, 1 bit, big-endian, init-value=0, base-type=boolean, compu {0..1=RANGE}, transfer-property=PENDING
          signal SESS_DIAG_oCAR_SUPERVISION_HDC_oCAN00: start 1, 1 bit, big-endian, init-value=0, base-type=boolean, compu {0..1=RANGE}, transfer-property=PENDING
          signal ETAT_NM_oCAR_SUPERVISION_HDC_oCAN00: start 3, 1 bit, big-endian, init-value=0, base-type=boolean, compu {0..1=RANGE}, transfer-property=PENDING
          signal BIT_NERR_oCAR_SUPERVISION_HDC_oCAN00: start 4, 1 bit, big-endian, init-value=0, base-type=boolean, compu {0..1=RANGE}, transfer-property=PENDING
          signal PERTE_COM_oCAR_SUPERVISION_HDC_oCAN00: start 5, 1 bit, big-endian, init-value=0, base-type=boolean, compu {0..1=RANGE}, transfer-property=PENDING
          signal C_DEFAUT_NERR_oCAR_SUPERVISION_HDC_oCAN00: start 15, 8 bit, big-endian, init-value=0, base-type=uint8, compu {0..255=RANGE}, transfer-property=PENDING
          signal C_DEFAUT_N_AS_oCAR_SUPERVISION_HDC_oCAN00: start 23, 8 bit, big-endian, init-value=0, base-type=uint8, compu {0..255=RANGE}, transfer-property=PENDING
          signal C_DEFAUT_BUSOFF_oCAR_SUPERVISION_HDC_oCAN00: start 31, 8 bit, big-endian, init-value=0, base-type=uint8, compu {0..255=RANGE}, transfer-property=PENDING
          signal C_DEFAUT_PERTE_COM_oCAR_SUPERVISION_HDC_oCAN00: start 39, 8 bit, big-endian, init-value=0, base-type=uint8, compu {0..255=RANGE}, transfer-property=PENDING
          signal UCE_ABS_HDC_oCAR_SUPERVISION_HDC_oCAN00: start 47, 6 bit, big-endian, init-value=0, base-type=uint8, compu {0..63=RANGE}, transfer-property=PENDING
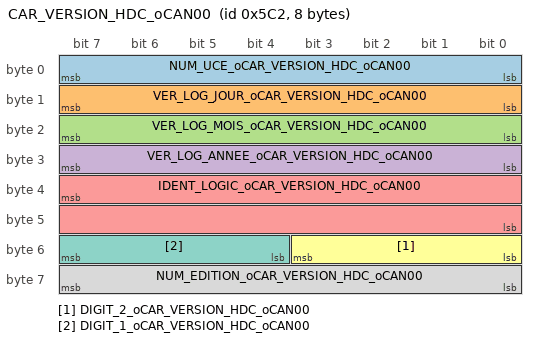
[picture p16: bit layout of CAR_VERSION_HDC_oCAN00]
      frame CAR_VERSION_HDC_oCAN00: id 0x5C2, from HDC, frame-length=8, can-addressing-mode=STANDARD
        pdu CAR_VERSION_HDC_oCAN00: length=8, minimum-delay=0, transmission-mode-false-timing=event-controlled-timing={number-of-repetitions=0, repetition-period=0}, transmission-mode-true-timing=event-controlled-timing={number-of-repetitions=0, repetition-period=0}, unused-bit-pattern=0
          signal NUM_UCE_oCAR_VERSION_HDC_oCAN00: start 7, 8 bit, big-endian, init-value=0, base-type=uint8, compu {0..254=RANGE}, transfer-property=TRIGGERED-WITHOUT-REPETITION
          signal VER_LOG_JOUR_oCAR_VERSION_HDC_oCAN00: start 15, 8 bit, big-endian, init-value=0, base-type=uint8, compu {1..31=RANGE}, transfer-property=PENDING
          signal VER_LOG_MOIS_oCAR_VERSION_HDC_oCAN00: start 23, 8 bit, big-endian, init-value=0, base-type=uint8, compu {1..12=RANGE}, transfer-property=PENDING
          signal VER_LOG_ANNEE_oCAR_VERSION_HDC_oCAN00: start 31, 8 bit, big-endian, init-value=0, base-type=uint8, compu {phys=raw+2000 for raw 0..200}, transfer-property=PENDING
          signal IDENT_LOGIC_oCAR_VERSION_HDC_oCAN00: start 39, 16 bit, big-endian, init-value=0, base-type=uint16, compu {0..65535=RANGE}, transfer-property=PENDING
          signal DIGIT_2_oCAR_VERSION_HDC_oCAN00: start 51, 4 bit, big-endian, init-value=0, base-type=uint8, compu {0..15=RANGE}, transfer-property=PENDING
          signal DIGIT_1_oCAR_VERSION_HDC_oCAN00: start 55, 4 bit, big-endian, init-value=0, base-type=uint8, compu {0..15=RANGE}, transfer-property=PENDING
          signal NUM_EDITION_oCAR_VERSION_HDC_oCAN00: start 63, 8 bit, big-endian, init-value=0, base-type=uint8, compu {0..254=RANGE}, transfer-property=PENDING
      frame CAR_VMF_DSGN_oCAN00: id 0xA2, from HDC, frame-length=6, can-addressing-mode=STANDARD
        pdu CAR_VMF_DSGN_oCAN00: length=6, minimum-delay=0.075, transmission-mode-false-timing=event-controlled-timing={number-of-repetitions=0, repetition-period=0}, transmission-mode-true-timing=event-controlled-timing={number-of-repetitions=0, repetition-period=0}, unused-bit-pattern=0
          signal CMPT_NAV_MENU_VMF_oCAR_VMF_DSGN_oCAN00: start 7, 8 bit, big-endian, init-value=0, base-type=sint8, compu {-128..127=RANGE}, transfer-property=TRIGGERED-ON-CHANGE-WITHOUT-REPETITION
          signal VMF_CDE_VOCALE_ET_VMF_oCAR_VMF_DSGN_oCAN00: start 8, 1 bit, big-endian, init-value=0, base-type=boolean, compu {0..1=RANGE}, transfer-property=TRIGGERED-ON-CHANGE-WITHOUT-REPETITION
          signal PSH_GH_ET_HDC_VMF_oCAR_VMF_DSGN_oCAN00: start 9, 1 bit, big-endian, init-value=0, base-type=boolean, compu {0..1=RANGE}, transfer-property=TRIGGERED-ON-CHANGE-WITHOUT-REPETITION
          signal MODE_ET_VMF_oCAR_VMF_DSGN_oCAN00: start 10, 1 bit, big-endian, init-value=0, base-type=boolean, compu {0..1=RANGE}, transfer-property=TRIGGERED-ON-CHANGE-WITHOUT-REPETITION
          signal MENU_ET_VMF_oCAR_VMF_DSGN_oCAN00: start 11, 1 bit, big-endian, init-value=0, base-type=boolean, compu {0..1=RANGE}, transfer-property=TRIGGERED-ON-CHANGE-WITHOUT-REPETITION
          signal ESCAPE_ET_VMF_oCAR_VMF_DSGN_oCAN00: start 12, 1 bit, big-endian, init-value=0, base-type=boolean, compu {0..1=RANGE}, transfer-property=TRIGGERED-ON-CHANGE-WITHOUT-REPETITION
          signal VALID_ET_VMF_oCAR_VMF_DSGN_oCAN00: start 13, 1 bit, big-endian, init-value=0, base-type=boolean, compu {0..1=RANGE}, transfer-property=TRIGGERED-ON-CHANGE-WITHOUT-REPETITION
          signal OVF_NAV_INF_ET_VMF_oCAR_VMF_DSGN_oCAN00: start 14, 1 bit, big-endian, init-value=0, base-type=boolean, compu {0..1=RANGE}, transfer-property=TRIGGERED-ON-CHANGE-WITHOUT-REPETITION
          signal OVF_NAV_SUP_ET_VMF_oCAR_VMF_DSGN_oCAN00: start 15, 1 bit, big-endian, init-value=0, base-type=boolean, compu {0..1=RANGE}, transfer-property=TRIGGERED-ON-CHANGE-WITHOUT-REPETITION
          signal CDE_TEL_KML_oCAR_VMF_DSGN_oCAN00: start 23, 1 bit, big-endian, init-value=0, base-type=boolean, compu {0..1=RANGE}, transfer-property=TRIGGERED-ON-CHANGE-WITHOUT-REPETITION
          signal CMPT_NAV_MENU_CMB_oCAR_VMF_DSGN_oCAN00: start 31, 8 bit, big-endian, init-value=0, base-type=sint8, compu {-128..127=RANGE}, transfer-property=TRIGGERED-ON-CHANGE-WITHOUT-REPETITION
          signal OVF_VOL_INF_ET_VCI_oCAR_VMF_DSGN_oCAN00: start 32, 1 bit, big-endian, init-value=0, base-type=boolean, compu {0..1=RANGE}, transfer-property=TRIGGERED-ON-CHANGE-WITHOUT-REPETITION
          signal OVF_VOL_SUP_ET_VCI_oCAR_VMF_DSGN_oCAN00: start 33, 1 bit, big-endian, init-value=0, base-type=boolean, compu {0..1=RANGE}, transfer-property=TRIGGERED-ON-CHANGE-WITHOUT-REPETITION
          signal RECYCL_AIR_ET_VMF_oCAR_VMF_DSGN_oCAN00: start 35, 1 bit, big-endian, init-value=0, base-type=boolean, compu {0..1=RANGE}, transfer-property=TRIGGERED-ON-CHANGE-WITHOUT-REPETITION
          signal ESCAPE_ET_CMB_oCAR_VMF_DSGN_oCAN00: start 36, 1 bit, big-endian, init-value=0, base-type=boolean, compu {0..1=RANGE}, transfer-property=TRIGGERED-ON-CHANGE-WITHOUT-REPETITION
          signal VALID_ET_CMB_oCAR_VMF_DSGN_oCAN00: start 37, 1 bit, big-endian, init-value=0, base-type=boolean, compu {0..1=RANGE}, transfer-property=TRIGGERED-ON-CHANGE-WITHOUT-REPETITION
          signal OVF_NAV_INF_ET_CMB_oCAR_VMF_DSGN_oCAN00: start 38, 1 bit, big-endian, init-value=0, base-type=boolean, compu {0..1=RANGE}, transfer-property=TRIGGERED-ON-CHANGE-WITHOUT-REPETITION
          signal OVF_NAV_SUP_ET_CMB_oCAR_VMF_DSGN_oCAN00: start 39, 1 bit, big-endian, init-value=0, base-type=boolean, compu {0..1=RANGE}, transfer-property=TRIGGERED-ON-CHANGE-WITHOUT-REPETITION
          signal CMPT_VOL_VCI_oCAR_VMF_DSGN_oCAN00: start 47, 8 bit, big-endian, init-value=0, base-type=sint8, compu {-128..127=RANGE}, transfer-property=TRIGGERED-ON-CHANGE-WITHOUT-REPETITION
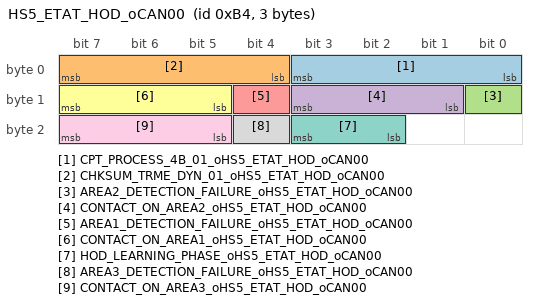
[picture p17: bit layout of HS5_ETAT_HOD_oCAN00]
      frame HS5_ETAT_HOD_oCAN00: id 0xB4, from HDC, frame-length=3, can-addressing-mode=STANDARD
        pdu HS5_ETAT_HOD_oCAN00: length=3, minimum-delay=0, transmission-mode-false-timing=cyclic-timing={time-offset=0, time-period=0.05}, transmission-mode-true-timing=cyclic-timing={time-offset=0, time-period=0.05}, unused-bit-pattern=0
          signal CPT_PROCESS_4B_01_oHS5_ETAT_HOD_oCAN00: start 3, 4 bit, big-endian, init-value=0, base-type=uint8, compu {0..15=RANGE}, transfer-property=PENDING
          signal CHKSUM_TRME_DYN_01_oHS5_ETAT_HOD_oCAN00: start 7, 4 bit, big-endian, init-value=0, base-type=uint8, compu {0..15=RANGE}, transfer-property=PENDING
          signal AREA2_DETECTION_FAILURE_oHS5_ETAT_HOD_oCAN00: start 8, 1 bit, big-endian, init-value=0, base-type=boolean, compu {0..1=RANGE}, transfer-property=PENDING
          signal CONTACT_ON_AREA2_oHS5_ETAT_HOD_oCAN00: start 11, 3 bit, big-endian, init-value=0, base-type=uint8, compu {0..7=RANGE}, transfer-property=PENDING
          signal AREA1_DETECTION_FAILURE_oHS5_ETAT_HOD_oCAN00: start 12, 1 bit, big-endian, init-value=0, base-type=boolean, compu {0..1=RANGE}, transfer-property=PENDING
          signal CONTACT_ON_AREA1_oHS5_ETAT_HOD_oCAN00: start 15, 3 bit, big-endian, init-value=0, base-type=uint8, compu {0..7=RANGE}, transfer-property=PENDING
          signal HOD_LEARNING_PHASE_oHS5_ETAT_HOD_oCAN00: start 19, 2 bit, big-endian, init-value=0, base-type=uint8, compu {0..3=RANGE}, transfer-property=PENDING
          signal AREA3_DETECTION_FAILURE_oHS5_ETAT_HOD_oCAN00: start 20, 1 bit, big-endian, init-value=0, base-type=boolean, compu {0..1=RANGE}, transfer-property=PENDING
          signal CONTACT_ON_AREA3_oHS5_ETAT_HOD_oCAN00: start 23, 3 bit, big-endian, init-value=0, base-type=uint8, compu {0..7=RANGE}, transfer-property=PENDING
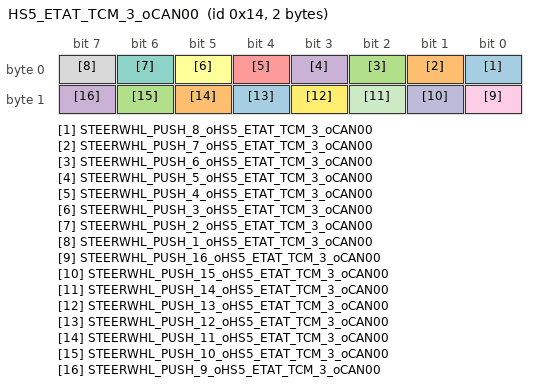
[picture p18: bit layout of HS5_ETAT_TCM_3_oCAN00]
      frame HS5_ETAT_TCM_3_oCAN00: id 0x14, from HDC, frame-length=2, can-addressing-mode=STANDARD
        pdu HS5_ETAT_TCM_3_oCAN00: length=2, minimum-delay=0.075, transmission-mode-false-timing=event-controlled-timing={number-of-repetitions=0, repetition-period=0}, transmission-mode-true-timing=event-controlled-timing={number-of-repetitions=0, repetition-period=0}, unused-bit-pattern=0
          signal STEERWHL_PUSH_8_oHS5_ETAT_TCM_3_oCAN00: start 0, 1 bit, big-endian, init-value=0, base-type=boolean, compu {0..1=RANGE}, transfer-property=TRIGGERED-ON-CHANGE-WITHOUT-REPETITION
          signal STEERWHL_PUSH_7_oHS5_ETAT_TCM_3_oCAN00: start 1, 1 bit, big-endian, init-value=0, base-type=boolean, compu {0..1=RANGE}, transfer-property=TRIGGERED-ON-CHANGE-WITHOUT-REPETITION
          signal STEERWHL_PUSH_6_oHS5_ETAT_TCM_3_oCAN00: start 2, 1 bit, big-endian, init-value=0, base-type=boolean, compu {0..1=RANGE}, transfer-property=TRIGGERED-ON-CHANGE-WITHOUT-REPETITION
          signal STEERWHL_PUSH_5_oHS5_ETAT_TCM_3_oCAN00: start 3, 1 bit, big-endian, init-value=0, base-type=boolean, compu {0..1=RANGE}, transfer-property=TRIGGERED-ON-CHANGE-WITHOUT-REPETITION
          signal STEERWHL_PUSH_4_oHS5_ETAT_TCM_3_oCAN00: start 4, 1 bit, big-endian, init-value=0, base-type=boolean, compu {0..1=RANGE}, transfer-property=TRIGGERED-ON-CHANGE-WITHOUT-REPETITION
          signal STEERWHL_PUSH_3_oHS5_ETAT_TCM_3_oCAN00: start 5, 1 bit, big-endian, init-value=0, base-type=boolean, compu {0..1=RANGE}, transfer-property=TRIGGERED-ON-CHANGE-WITHOUT-REPETITION
          signal STEERWHL_PUSH_2_oHS5_ETAT_TCM_3_oCAN00: start 6, 1 bit, big-endian, init-value=0, base-type=boolean, compu {0..1=RANGE}, transfer-property=TRIGGERED-ON-CHANGE-WITHOUT-REPETITION
          signal STEERWHL_PUSH_1_oHS5_ETAT_TCM_3_oCAN00: start 7, 1 bit, big-endian, init-value=0, base-type=boolean, compu {0..1=RANGE}, transfer-property=TRIGGERED-ON-CHANGE-WITHOUT-REPETITION
          signal STEERWHL_PUSH_16_oHS5_ETAT_TCM_3_oCAN00: start 8, 1 bit, big-endian, init-value=0, base-type=boolean, compu {0..1=RANGE}, transfer-property=TRIGGERED-ON-CHANGE-WITHOUT-REPETITION
          signal STEERWHL_PUSH_15_oHS5_ETAT_TCM_3_oCAN00: start 9, 1 bit, big-endian, init-value=0, base-type=boolean, compu {0..1=RANGE}, transfer-property=TRIGGERED-ON-CHANGE-WITHOUT-REPETITION
          signal STEERWHL_PUSH_14_oHS5_ETAT_TCM_3_oCAN00: start 10, 1 bit, big-endian, init-value=0, base-type=boolean, compu {0..1=RANGE}, transfer-property=TRIGGERED-ON-CHANGE-WITHOUT-REPETITION
          signal STEERWHL_PUSH_13_oHS5_ETAT_TCM_3_oCAN00: start 11, 1 bit, big-endian, init-value=0, base-type=boolean, compu {0..1=RANGE}, transfer-property=TRIGGERED-ON-CHANGE-WITHOUT-REPETITION
          signal STEERWHL_PUSH_12_oHS5_ETAT_TCM_3_oCAN00: start 12, 1 bit, big-endian, init-value=0, base-type=boolean, compu {0..1=RANGE}, transfer-property=TRIGGERED-ON-CHANGE-WITHOUT-REPETITION
          signal STEERWHL_PUSH_11_oHS5_ETAT_TCM_3_oCAN00: start 13, 1 bit, big-endian, init-value=0, base-type=boolean, compu {0..1=RANGE}, transfer-property=TRIGGERED-ON-CHANGE-WITHOUT-REPETITION
          signal STEERWHL_PUSH_10_oHS5_ETAT_TCM_3_oCAN00: start 14, 1 bit, big-endian, init-value=0, base-type=boolean, compu {0..1=RANGE}, transfer-property=TRIGGERED-ON-CHANGE-WITHOUT-REPETITION
          signal STEERWHL_PUSH_9_oHS5_ETAT_TCM_3_oCAN00: start 15, 1 bit, big-endian, init-value=0, base-type=boolean, compu {0..1=RANGE}, transfer-property=TRIGGERED-ON-CHANGE-WITHOUT-REPETITION
      frame HS5_REP_DIAG_TCM_HOD_oCAN00: id 0x656, from HDC, frame-length=8, can-addressing-mode=STANDARD
        n pdu HS5_REP_DIAG_TCM_HOD_Tp_oCAN00: length=8
      frame HS5_REP_DIAG_TCM_SWH_oCAN00: id 0x678, from HDC, frame-length=8, can-addressing-mode=STANDARD
        n pdu HS5_REP_DIAG_TCM_SWH_Tp_oCAN00: length=8
      frame HS5_REQ_DIAG_TCM_HOD_oCAN00: id 0x676, to HDC, frame-length=8, can-addressing-mode=STANDARD
        n pdu HS5_REQ_DIAG_TCM_HOD_Tp_oCAN00: length=8
      frame HS5_REQ_DIAG_TCM_SWH_oCAN00: id 0x698, to HDC, frame-length=8, can-addressing-mode=STANDARD
        n pdu HS5_REQ_DIAG_TCM_SWH_Tp_oCAN00: length=8
      pdu triggering PT_CAR_REP_DIAG_HDC: pdu=CAR_REP_DIAG_HDC_oCAN00, from HDC
      pdu triggering PT_CAR_REP_DIAG_HDC_VCI: pdu=CAR_REP_DIAG_HDC_VCI_oCAN00, from HDC
      pdu triggering PT_CAR_REQ_DIAG_HDC: pdu=CAR_REQ_DIAG_HDC_oCAN00, to HDC
      pdu triggering PT_CAR_REQ_DIAG_HDC_VCI: pdu=CAR_REQ_DIAG_HDC_VCI_oCAN00, to HDC
      pdu triggering PT_HS5_REP_DIAG_TCM_HOD: pdu=HS5_REP_DIAG_TCM_HOD_oCAN00, from HDC
      pdu triggering PT_HS5_REP_DIAG_TCM_SWH: pdu=HS5_REP_DIAG_TCM_SWH_oCAN00, from HDC
      pdu triggering PT_HS5_REQ_DIAG_TCM_HOD: pdu=HS5_REQ_DIAG_TCM_HOD_oCAN00, to HDC
      pdu triggering PT_HS5_REQ_DIAG_TCM_SWH: pdu=HS5_REQ_DIAG_TCM_SWH_oCAN00, to HDC
package /ECU
  ecu instance HDC: associated-com-i-pdu-group=[HDC_oCAN00_Rx, HDC_oCAN00_Tx]
    can communication controller CT_CAN00
    can communication connector CN_CAN00: comm-controller=CT_CAN00
package /IPDUGroup
  i signal i pdu group HDC_oCAN00_Rx: communication-direction=IN
    i-signal-i-pdus:
      CAR_ACK_EVT_DEF_oCAN00
      CAR_CDE_HDC_oCAN00
      CAR_CMD_AUTHENT_MDP_AES_oCAN00
      CAR_CMD_AUTHENT_oCAN00
      CAR_CMD_AUTHENT_RND_AES_oCAN00
      CAR_CMD_LECT_oCAN00
      CAR_COMMANDE_BRT_oCAN00
      CAR_COMMANDES_BSI_oCAN00
      CAR_DIAG_UDS_ON_CAN_oCAN00
      CAR_DONNEES_BSI_LENTES_2_oCAN00
      CAR_DONNEES_BSI_LENTES_oCAN00
      CAR_IDENT_HF_oCAN00
      CAR_PROG_TRSP_AUTHENT_AES_1_oCAN00
      CAR_PROG_TRSP_AUTHENT_oCAN00
      CAR_PROG_TRSP_AUTHENT_RSK16_oCAN00
      CAR_PROG_TRSP_PASS_oCAN00
  i signal i pdu group HDC_oCAN00_Tx: communication-direction=OUT
    i-signal-i-pdus:
      CAR_CDE_RADIO_oCAN00
      CAR_ETAT_HDC_oCAN00
      CAR_ETAT_TRSP_oCAN00
      CAR_EVT_DEFAUT_HDC_oCAN00
      CAR_MESSAGE_HF_oCAN00
      CAR_REPONSE_AUTHENT_AES_oCAN00
      CAR_REPONSE_AUTHENT_oCAN00
      CAR_REVEIL_HDC_oCAN00
      CAR_SUPERVISION_HDC_oCAN00
      CAR_VERSION_HDC_oCAN00
      CAR_VMF_DSGN_oCAN00
      HS5_ETAT_HOD_oCAN00
      HS5_ETAT_TCM_3_oCAN00
package /PDU
  dcm i pdu CAR_REP_DIAG_HDC_oCAN00: length=8, diag-pdu-type=DIAG-RESPONSE
  dcm i pdu CAR_REP_DIAG_HDC_VCI_oCAN00: length=8, diag-pdu-type=DIAG-RESPONSE
  dcm i pdu CAR_REQ_DIAG_HDC_oCAN00: length=8, diag-pdu-type=DIAG-REQUEST
  dcm i pdu CAR_REQ_DIAG_HDC_VCI_oCAN00: length=8, diag-pdu-type=DIAG-REQUEST
  dcm i pdu HS5_REP_DIAG_TCM_HOD_oCAN00: length=8, diag-pdu-type=DIAG-RESPONSE
  dcm i pdu HS5_REP_DIAG_TCM_SWH_oCAN00: length=8, diag-pdu-type=DIAG-RESPONSE
  dcm i pdu HS5_REQ_DIAG_TCM_HOD_oCAN00: length=8, diag-pdu-type=DIAG-REQUEST
  dcm i pdu HS5_REQ_DIAG_TCM_SWH_oCAN00: length=8, diag-pdu-type=DIAG-REQUEST
package /ISignal
  i signal group SG_CODE_HF_ET_HF_GROUP_oCAR_MESSAGE_HF_oCAN00: i-signal=[CODE_HF_ET_HF1_oCAR_MESSAGE_HF_oCAN00, CODE_HF_ET_HF2_oCAR_MESSAGE_HF_oCAN00, CODE_HF_ET_HF3_oCAR_MESSAGE_HF_oCAN00, CODE_HF_ET_HF4_oCAR_MESSAGE_HF_oCAN00, CODE_HF_ET_HF5_oCAR_MESSAGE_HF_oCAN00, CODE_HF_ET_HF6_oCAR_MESSAGE_HF_oCAN00, CODE_HF_ET_HF7_oCAR_MESSAGE_HF_oCAN00, CODE_HF_ET_HF8_oCAR_MESSAGE_HF_oCAN00], system-signal-group=SG_CODE_HF_ET_HF_GROUP
package /DataType
  base type uint8_6_iso_8859_1: category=FIXED_LENGTH, base-type-size=48, base-type-encoding=ISO-8859-1
  base type uint8_7_iso_8859_1: category=FIXED_LENGTH, base-type-size=56, base-type-encoding=ISO-8859-1
  base type uint8_8_iso_8859_1: category=FIXED_LENGTH, base-type-size=64, base-type-encoding=ISO-8859-1
